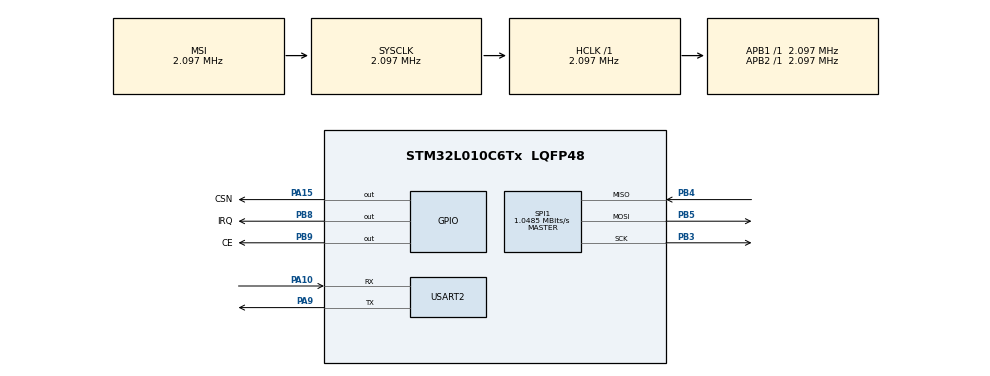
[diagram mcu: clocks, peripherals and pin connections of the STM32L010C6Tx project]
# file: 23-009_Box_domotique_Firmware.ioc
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Dma.Request0=USART2_RX
Dma.USART2_RX.0.Direction=DMA_PERIPH_TO_MEMORY
Dma.USART2_RX.0.Instance=DMA1_Channel5
Dma.USART2_RX.0.MemDataAlignment=DMA_MDATAALIGN_BYTE
Dma.USART2_RX.0.MemInc=DMA_MINC_ENABLE
Dma.USART2_RX.0.Mode=DMA_CIRCULAR
Dma.USART2_RX.0.PeriphDataAlignment=DMA_PDATAALIGN_BYTE
Dma.USART2_RX.0.PeriphInc=DMA_PINC_DISABLE
Dma.USART2_RX.0.Priority=DMA_PRIORITY_LOW
Mcu.Family=STM32L0
Mcu.Name=STM32L010C6Tx
Mcu.Package=LQFP48
NVIC.DMA1_Channel4_5_6_7_IRQn=true\:0\:0\:false\:false\:true\:false\:true\:true
NVIC.USART2_IRQn=true\:0\:0\:false\:false\:true\:true\:true\:true
PA10.Mode=Asynchronous
PA10.Signal=USART2_RX
PA15.GPIO_Label=CSN
PA15.Signal=GPIO_Output
PA9.Mode=Asynchronous
PA9.Signal=USART2_TX
PB3.Mode=Full_Duplex_Master
PB3.Signal=SPI1_SCK
PB4.Mode=Full_Duplex_Master
PB4.Signal=SPI1_MISO
PB5.Mode=Full_Duplex_Master
PB5.Signal=SPI1_MOSI
PB8.GPIO_Label=IRQ
PB8.Signal=GPIO_Output
PB9.GPIO_Label=CE
PB9.Signal=GPIO_Output
ProjectManager.HeapSize=0x200
ProjectManager.StackSize=0x400
ProjectManager.TargetToolchain=STM32CubeIDE
RCC.AHBFreq_Value=2097000
RCC.APB1Freq_Value=2097000
RCC.APB1TimFreq_Value=2097000
RCC.APB2Freq_Value=2097000
RCC.APB2TimFreq_Value=2097000
RCC.HCLKFreq_Value=2097000
RCC.HSE_VALUE=8000000
RCC.HSI16_VALUE=16000000
RCC.HSI_VALUE=16000000
RCC.LSE_VALUE=32768
RCC.MSI_VALUE=2097000
RCC.SYSCLKFreq_VALUE=2097000
RCC.Usart2ClockSelection=RCC_USART2CLKSOURCE_HSI
RCC.VCOOutputFreq_Value=48000000
RTC.Date=17
RTC.Month=RTC_MONTH_APRIL
RTC.WeekDay=RTC_WEEKDAY_FRIDAY
RTC.Year=15
SPI1.CalculateBaudRate=1.0485 MBits/s
SPI1.Direction=SPI_DIRECTION_2LINES
SPI1.Mode=SPI_MODE_MASTER
SPI1.VirtualType=VM_MASTER
USART2.VirtualMode=VM_ASYNC
VP_RTC_VS_RTC_Activate.Mode=RTC_Enabled
VP_RTC_VS_RTC_Calendar.Mode=RTC_Calendar
board=custom

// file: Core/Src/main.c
/* USER CODE BEGIN Header */
/**
  ******************************************************************************
  * @file           : main.c
  * @brief          : Main program body
  ******************************************************************************
  * @attention
  *
  * Copyright (c) 2023 STMicroelectronics.
  * All rights reserved.
  *
  * This software is licensed under terms that can be found in the LICENSE file
  * in the root directory of this software component.
  * If no LICENSE file comes with this software, it is provided AS-IS.
  *
  ******************************************************************************
  */
/* USER CODE END Header */
#include "main.h"

/* USER CODE BEGIN Includes */
#include "string.h"
#include "hal.h"
#include "tools.h"
#include "Ted24.h"
#include "NRF24L01.h"
#include "configuration.h"
#include "debug.h"
#include "Application.h"
#include "stm32l0xx_ll_usart.h"
/* USER CODE END Includes */

RTC_HandleTypeDef hrtc;

SPI_HandleTypeDef hspi1;

UART_HandleTypeDef huart2;
DMA_HandleTypeDef hdma_usart2_rx;

void SystemClock_Config(void);
static void MX_GPIO_Init(void);
static void MX_DMA_Init(void);
static void MX_USART2_UART_Init(void);
static void MX_SPI1_Init(void);
static void MX_RTC_Init(void);

int main(void)
{

  /* MCU Configuration--------------------------------------------------------*/

  /* Reset of all peripherals, Initializes the Flash interface and the Systick. */
  HAL_Init();

  /* Configure the system clock */
  SystemClock_Config();

  /* Initialize all configured peripherals */
  MX_GPIO_Init();
  MX_DMA_Init();
  MX_USART2_UART_Init();
  MX_SPI1_Init();
  MX_RTC_Init();
  /* USER CODE BEGIN 2 */
  runApp();
  /* USER CODE END 2 */

  /* Infinite loop */
  while (1)
  {

  }
}

void SystemClock_Config(void)
{
  RCC_OscInitTypeDef RCC_OscInitStruct = {0};
  RCC_ClkInitTypeDef RCC_ClkInitStruct = {0};
  RCC_PeriphCLKInitTypeDef PeriphClkInit = {0};

  /** Configure the main internal regulator output voltage
  */
  __HAL_PWR_VOLTAGESCALING_CONFIG(PWR_REGULATOR_VOLTAGE_SCALE1);

  /** Initializes the RCC Oscillators according to the specified parameters
  * in the RCC_OscInitTypeDef structure.
  */
  RCC_OscInitStruct.OscillatorType = RCC_OSCILLATORTYPE_HSI|RCC_OSCILLATORTYPE_LSI
                              |RCC_OSCILLATORTYPE_MSI;
  RCC_OscInitStruct.HSIState = RCC_HSI_ON;
  RCC_OscInitStruct.HSICalibrationValue = RCC_HSICALIBRATION_DEFAULT;
  RCC_OscInitStruct.LSIState = RCC_LSI_ON;
  RCC_OscInitStruct.MSIState = RCC_MSI_ON;
  RCC_OscInitStruct.MSICalibrationValue = 0;
  RCC_OscInitStruct.MSIClockRange = RCC_MSIRANGE_5;
  RCC_OscInitStruct.PLL.PLLState = RCC_PLL_NONE;
  if (HAL_RCC_OscConfig(&RCC_OscInitStruct) != HAL_OK)
  {
    Error_Handler();
  }

  /** Initializes the CPU, AHB and APB buses clocks
  */
  RCC_ClkInitStruct.ClockType = RCC_CLOCKTYPE_HCLK|RCC_CLOCKTYPE_SYSCLK
                              |RCC_CLOCKTYPE_PCLK1|RCC_CLOCKTYPE_PCLK2;
  RCC_ClkInitStruct.SYSCLKSource = RCC_SYSCLKSOURCE_MSI;
  RCC_ClkInitStruct.AHBCLKDivider = RCC_SYSCLK_DIV1;
  RCC_ClkInitStruct.APB1CLKDivider = RCC_HCLK_DIV1;
  RCC_ClkInitStruct.APB2CLKDivider = RCC_HCLK_DIV1;

  if (HAL_RCC_ClockConfig(&RCC_ClkInitStruct, FLASH_LATENCY_0) != HAL_OK)
  {
    Error_Handler();
  }
  PeriphClkInit.PeriphClockSelection = RCC_PERIPHCLK_USART2|RCC_PERIPHCLK_RTC;
  PeriphClkInit.Usart2ClockSelection = RCC_USART2CLKSOURCE_HSI;
  PeriphClkInit.RTCClockSelection = RCC_RTCCLKSOURCE_LSI;
  if (HAL_RCCEx_PeriphCLKConfig(&PeriphClkInit) != HAL_OK)
  {
    Error_Handler();
  }
}

static void MX_RTC_Init(void)
{

  RTC_TimeTypeDef sTime = {0};
  RTC_DateTypeDef sDate = {0};

  /** Initialize RTC Only
  */
  hrtc.Instance = RTC;
  hrtc.Init.HourFormat = RTC_HOURFORMAT_24;
  hrtc.Init.AsynchPrediv = 127;
  hrtc.Init.SynchPrediv = 255;
  hrtc.Init.OutPut = RTC_OUTPUT_DISABLE;
  hrtc.Init.OutPutRemap = RTC_OUTPUT_REMAP_NONE;
  hrtc.Init.OutPutPolarity = RTC_OUTPUT_POLARITY_HIGH;
  hrtc.Init.OutPutType = RTC_OUTPUT_TYPE_OPENDRAIN;
  if (HAL_RTC_Init(&hrtc) != HAL_OK)
  {
    Error_Handler();
  }

  /** Initialize RTC and set the Time and Date
  */
  sTime.Hours = 0;
  sTime.Minutes = 0;
  sTime.Seconds = 0;
  sTime.DayLightSaving = RTC_DAYLIGHTSAVING_NONE;
  sTime.StoreOperation = RTC_STOREOPERATION_RESET;
  if (HAL_RTC_SetTime(&hrtc, &sTime, RTC_FORMAT_BIN) != HAL_OK)
  {
    Error_Handler();
  }
  sDate.WeekDay = RTC_WEEKDAY_FRIDAY;
  sDate.Month = RTC_MONTH_APRIL;
  sDate.Date = 17;
  sDate.Year = 15;

  if (HAL_RTC_SetDate(&hrtc, &sDate, RTC_FORMAT_BIN) != HAL_OK)
  {
    Error_Handler();
  }

  /** Enable the WakeUp
  */
  if (HAL_RTCEx_SetWakeUpTimer_IT(&hrtc, 0, RTC_WAKEUPCLOCK_CK_SPRE_16BITS) != HAL_OK)
  {
    Error_Handler();
  }

}

static void MX_SPI1_Init(void)
{

  /* SPI1 parameter configuration*/
  hspi1.Instance = SPI1;
  hspi1.Init.Mode = SPI_MODE_MASTER;
  hspi1.Init.Direction = SPI_DIRECTION_2LINES;
  hspi1.Init.DataSize = SPI_DATASIZE_8BIT;
  hspi1.Init.CLKPolarity = SPI_POLARITY_LOW;
  hspi1.Init.CLKPhase = SPI_PHASE_1EDGE;
  hspi1.Init.NSS = SPI_NSS_SOFT;
  hspi1.Init.BaudRatePrescaler = SPI_BAUDRATEPRESCALER_2;
  hspi1.Init.FirstBit = SPI_FIRSTBIT_MSB;
  hspi1.Init.TIMode = SPI_TIMODE_DISABLE;
  hspi1.Init.CRCCalculation = SPI_CRCCALCULATION_DISABLE;
  hspi1.Init.CRCPolynomial = 7;
  if (HAL_SPI_Init(&hspi1) != HAL_OK)
  {
    Error_Handler();
  }

}

static void MX_USART2_UART_Init(void)
{

  huart2.Instance = USART2;
  huart2.Init.BaudRate = 115200;
  huart2.Init.WordLength = UART_WORDLENGTH_8B;
  huart2.Init.StopBits = UART_STOPBITS_1;
  huart2.Init.Parity = UART_PARITY_NONE;
  huart2.Init.Mode = UART_MODE_TX_RX;
  huart2.Init.HwFlowCtl = UART_HWCONTROL_NONE;
  huart2.Init.OverSampling = UART_OVERSAMPLING_16;
  huart2.Init.OneBitSampling = UART_ONE_BIT_SAMPLE_DISABLE;
  huart2.AdvancedInit.AdvFeatureInit = UART_ADVFEATURE_NO_INIT;
  if (HAL_UART_Init(&huart2) != HAL_OK)
  {
    Error_Handler();
  }

}

static void MX_DMA_Init(void)
{

  /* DMA controller clock enable */
  __HAL_RCC_DMA1_CLK_ENABLE();

  /* DMA interrupt init */
  /* DMA1_Channel4_5_6_7_IRQn interrupt configuration */
  HAL_NVIC_SetPriority(DMA1_Channel4_5_6_7_IRQn, 0, 0);
  HAL_NVIC_EnableIRQ(DMA1_Channel4_5_6_7_IRQn);

}

static void MX_GPIO_Init(void)
{
  GPIO_InitTypeDef GPIO_InitStruct = {0};

  /* GPIO Ports Clock Enable */
  __HAL_RCC_GPIOA_CLK_ENABLE();
  __HAL_RCC_GPIOB_CLK_ENABLE();

  /*Configure GPIO pin Output Level */
  HAL_GPIO_WritePin(CSN_GPIO_Port, CSN_Pin, GPIO_PIN_RESET);

  /*Configure GPIO pin Output Level */
  HAL_GPIO_WritePin(GPIOB, IRQ_Pin|CE_Pin, GPIO_PIN_RESET);

  /*Configure GPIO pin : CSN_Pin */
  GPIO_InitStruct.Pin = CSN_Pin;
  GPIO_InitStruct.Mode = GPIO_MODE_OUTPUT_PP;
  GPIO_InitStruct.Pull = GPIO_NOPULL;
  GPIO_InitStruct.Speed = GPIO_SPEED_FREQ_LOW;
  HAL_GPIO_Init(CSN_GPIO_Port, &GPIO_InitStruct);

  /*Configure GPIO pins : IRQ_Pin CE_Pin */
  GPIO_InitStruct.Pin = IRQ_Pin|CE_Pin;
  GPIO_InitStruct.Mode = GPIO_MODE_OUTPUT_PP;
  GPIO_InitStruct.Pull = GPIO_NOPULL;
  GPIO_InitStruct.Speed = GPIO_SPEED_FREQ_LOW;
  HAL_GPIO_Init(GPIOB, &GPIO_InitStruct);

}

void Error_Handler(void)
{
  __disable_irq();
  while (1)
  {
  }
}
